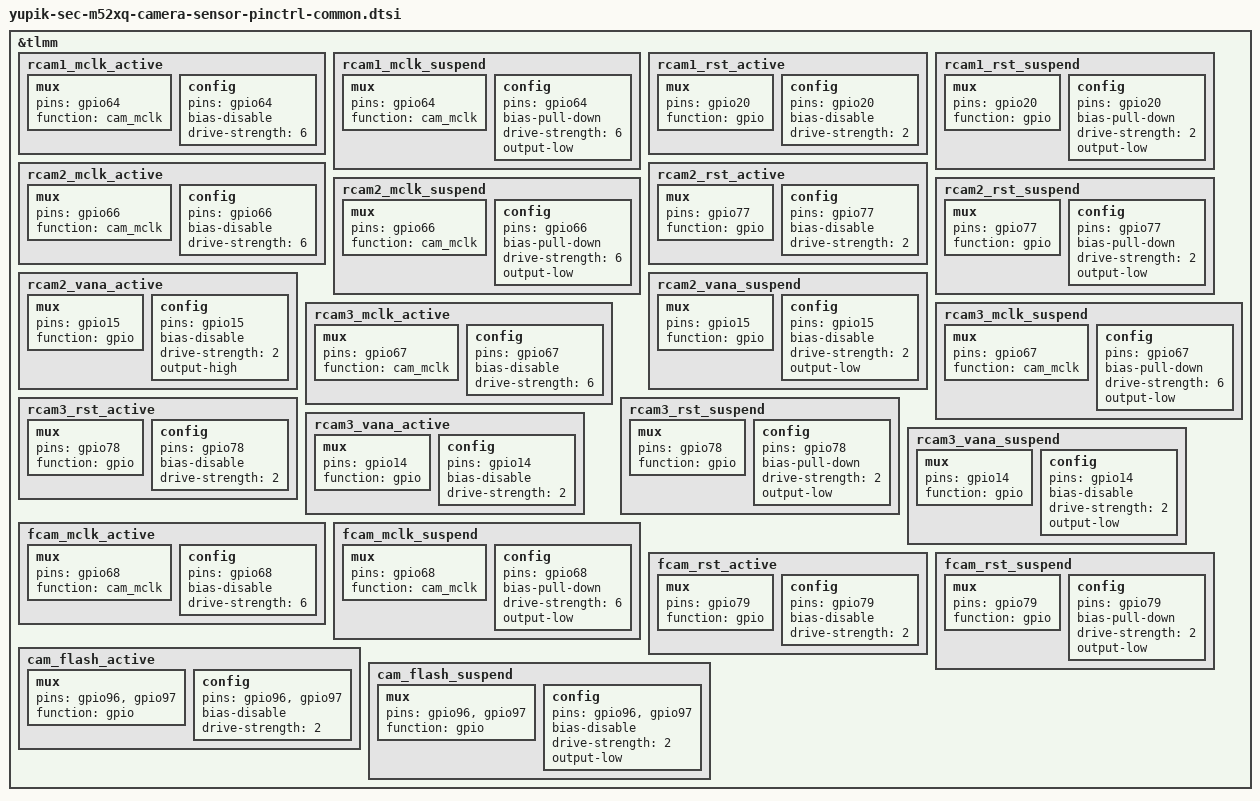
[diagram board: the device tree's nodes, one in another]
/* Copyright (c) 2021, The Linux Foundation. All rights reserved.
 *
 * This program is free software; you can redistribute it and/or modify
 * it under the terms of the GNU General Public License version 2 and
 * only version 2 as published by the Free Software Foundation.
 *
 * This program is distributed in the hope that it will be useful,
 * but WITHOUT ANY WARRANTY; without even the implied warranty of
 * MERCHANTABILITY or FITNESS FOR A PARTICULAR PURPOSE.  See the
 * GNU General Public License for more details.
 */

&tlmm {

/*
 * RCAM id 0
 */
	rcam1_mclk_active: rcam1_mclk_active {
		/* Main Rear1 MCLK */
		mux {
			pins = "gpio64";
			function = "cam_mclk";
		};
		config {
			pins = "gpio64";
			bias-disable; /* No PULL */
			drive-strength = <6>; /* 6 MA */
		};
	};

	rcam1_mclk_suspend: rcam1_mclk_suspend {
		/* Main Rear1 MCLK */
		mux {
			pins = "gpio64";
			function = "cam_mclk";
		};
		config {
			pins = "gpio64";
			bias-pull-down; /* No PULL */
			drive-strength = <6>; /* 6 MA */
			output-low;
		};
	};

	rcam1_rst_active: rcam1_rst_active {
		/* Main Rear1 RESET */
		mux {
			pins = "gpio20";
			function = "gpio";
		};
		config {
			pins = "gpio20";
			bias-disable; /* No PULL */
			drive-strength = <2>; /* 2 MA */
		};
	};

	rcam1_rst_suspend: rcam1_rst_suspend {
		/* Main Rear1 RESET */
		mux {
			pins = "gpio20";
			function = "gpio";
		};
		config {
			pins = "gpio20";
			bias-pull-down; /* No PULL */
			drive-strength = <2>; /* 2 MA */
			output-low;
		};
	};
/*
 * RCAM id 2
 */
	rcam2_mclk_active: rcam2_mclk_active {
		/* Main Rear2 MCLK */
		mux {
			pins = "gpio66";
			function = "cam_mclk";
		};
		config {
			pins = "gpio66";
			bias-disable; /* No PULL */
			drive-strength = <6>; /* 6 MA */
		};
	};

	rcam2_mclk_suspend: rcam2_mclk_suspend {
		/* Main Rear2 MCLK */
		mux {
			pins = "gpio66";
			function = "cam_mclk";
		};
		config {
			pins = "gpio66";
			bias-pull-down; /* No PULL */
			drive-strength = <6>; /* 6 MA */
			output-low;
		};
	};

	rcam2_rst_active: rcam2_rst_active {
		/* Main Rear2 RESET */
		mux {
			pins = "gpio77";
			function = "gpio";
		};
		config {
			pins = "gpio77";
			bias-disable; /* No PULL */
			drive-strength = <2>; /* 2 MA */
		};
	};

	rcam2_rst_suspend: rcam2_rst_suspend {
		/* Main Rear2 RESET */
		mux {
			pins = "gpio77";
			function = "gpio";
		};
		config {
			pins = "gpio77";
			bias-pull-down; /* No PULL */
			drive-strength = <2>; /* 2 MA */
			output-low;
		};
	};

	rcam2_vana_active: rcam2_vana_active {
		/* Main Rear2 VANA */
		mux {
			pins = "gpio15";
			function = "gpio";
		};
		config {
			pins = "gpio15";
			bias-disable; /* No PULL */
			drive-strength = <2>; /* 2 MA */
			output-high;
		};
	};

	rcam2_vana_suspend: rcam2_vana_suspend {
		/* Main Rear2 VANA */
		mux {
			pins = "gpio15";
			function = "gpio";
		};
		config {
			pins = "gpio15";
			bias-disable; /* No PULL */
			drive-strength = <2>; /* 2 MA */
			output-low;
		};
	};

/*
 * RCAM id 3
 */
	rcam3_mclk_active: rcam3_mclk_active {
		/* Main Rear3 MCLK */
		mux {
			pins = "gpio67";
			function = "cam_mclk";
		};
		config {
			pins = "gpio67";
			bias-disable; /* No PULL */
			drive-strength = <6>; /* 6 MA */
		};
	};

	rcam3_mclk_suspend: rcam3_mclk_suspend {
		/* Main Rear3 MCLK */
		mux {
			pins = "gpio67";
			function = "cam_mclk";
		};
		config {
			pins = "gpio67";
			bias-pull-down; /* No PULL */
			drive-strength = <6>; /* 6 MA */
			output-low;
		};
	};

	rcam3_rst_active: rcam3_rst_active {
		/* Main Rear3 RESET */
		mux {
			pins = "gpio78";
			function = "gpio";
		};
		config {
			pins = "gpio78";
			bias-disable; /* No PULL */
			drive-strength = <2>; /* 2 MA */
		};
	};

	rcam3_rst_suspend: rcam3_rst_suspend {
		/* Main Rear3 RESET */
		mux {
			pins = "gpio78";
			function = "gpio";
		};
		config {
			pins = "gpio78";
			bias-pull-down; /* No PULL */
			drive-strength = <2>; /* 2 MA */
			output-low;
		};
	};

	rcam3_vana_active: rcam3_vana_active {
		/* Main Rear3 VANA */
		mux {
			pins = "gpio14";
			function = "gpio";
		};
		config {
			pins = "gpio14";
			bias-disable; /* No PULL */
			drive-strength = <2>; /* 2 MA */
		};
	};

	rcam3_vana_suspend: rcam3_vana_suspend {
		/* Main Rear3 VANA */
		mux {
			pins = "gpio14";
			function = "gpio";
		};
		config {
			pins = "gpio14";
			bias-disable; /* No PULL */
			drive-strength = <2>; /* 2 MA */
			output-low;
		};
	};
/*
 * FCAM id 1
 */
	fcam_mclk_active: fcam_mclk_active {
		/* Main FCAM MCLK */
		mux {
			pins = "gpio68";
			function = "cam_mclk";
		};
		config {
			pins = "gpio68";
			bias-disable; /* No PULL */
			drive-strength = <6>; /* 6 MA */
		};
	};

	fcam_mclk_suspend: fcam_mclk_suspend {
		/* Main FCAM MCLK */
		mux {
			pins = "gpio68";
			function = "cam_mclk";
		};
		config {
			pins = "gpio68";
			bias-pull-down; /* No PULL */
			drive-strength = <6>; /* 6 MA */
			output-low;
		};
	};

	fcam_rst_active: fcam_rst_active {
		/* Main FCAM RESET */
		mux {
			pins = "gpio79";
			function = "gpio";
		};
		config {
			pins = "gpio79";
			bias-disable; /* No PULL */
			drive-strength = <2>; /* 2 MA */
		};
	};

	fcam_rst_suspend: fcam_rst_suspend {
		/* Main FCAM RESET */
		mux {
			pins = "gpio79";
			function = "gpio";
		};
		config {
			pins = "gpio79";
			bias-pull-down; /* No PULL */
			drive-strength = <2>; /* 2 MA */
			output-low;
		};
	};
	
	cam_flash_active: cam_flash_active {
	/* TORCH, FLASH */
		mux {
			pins = "gpio96", "gpio97";
			function = "gpio";
		};
		config {
			pins = "gpio96", "gpio97";
			bias-disable; /* No PULL */
			drive-strength = <2>; /* 2 MA */
		};
	};

	cam_flash_suspend: cam_flash_suspend {
	/* TORCH, FLASH */
		mux {
			pins = "gpio96", "gpio97";
			function = "gpio";
		};
		config {
			pins = "gpio96", "gpio97";
			bias-disable; /* No PULL */
			drive-strength = <2>; /* 2 MA */
			output-low;
		};
	};
};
